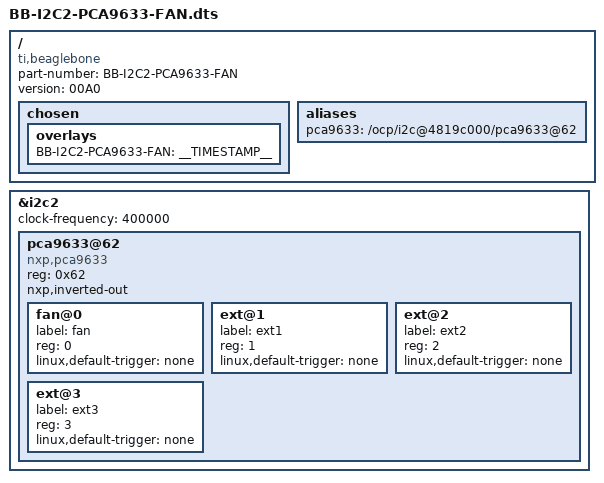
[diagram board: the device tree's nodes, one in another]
/*
 * Copyright (C) 2020 Seeed Studio
 * Peter Yang <turmary@126.com>
 *
 * MIT License
 *
 */
/dts-v1/;
/plugin/;

/ {
        compatible = "ti,beaglebone", "ti,beaglebone-black", "ti,beaglebone-green";

	/* identification */
	part-number = "BB-I2C2-PCA9633-FAN";
	version = "00A0";

	fragment@0 {
		target-path="/";
		__overlay__ {
			chosen {
				overlays {
					BB-I2C2-PCA9633-FAN = __TIMESTAMP__;
				};
			};

			aliases {
				/* SLOT I2C1 */
				/*
				lis331dlh = "/ocp/i2c@4802a000/lis331dlh@18";
				*/
				/* SLOT I2C2 */
				pca9633 = "/ocp/i2c@4819c000/pca9633@62";
			};
		};
	};

	fragment@1 {
		/* SLOT I2C1 */
		/*
		target = <&i2c1>;
		*/
		/* SLOT I2C2 */
		target = <&i2c2>;

		__overlay__ {
			status = "okay";

			/* this is the configuration part */
			clock-frequency = <400000>;

			#address-cells = <1>;
			#size-cells = <0>;

			pca9633@62 {
				compatible = "nxp,pca9633";
				reg = <0x62>;
				status = "okay";

				#address-cells = <1>;
				#size-cells = <0>;

				nxp,inverted-out;

				fan@0 {
					label = "fan";
					reg = <0>;
					linux,default-trigger = "none";
				};

				ext@1 {
					label = "ext1";
					reg = <1>;
					linux,default-trigger = "none";
				};

				ext@2 {
					label = "ext2";
					reg = <2>;
					linux,default-trigger = "none";
				};

				ext@3 {
					label = "ext3";
					reg = <3>;
					linux,default-trigger = "none";
				};
			};
		};
	};
};

